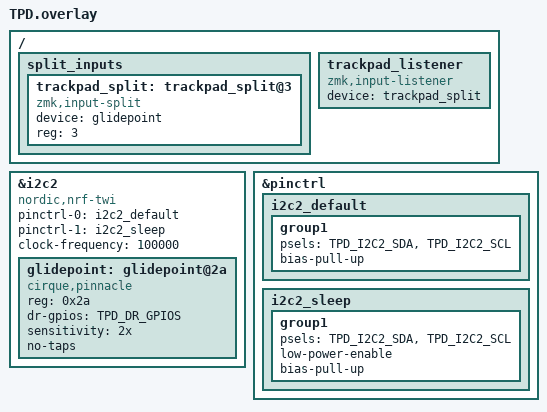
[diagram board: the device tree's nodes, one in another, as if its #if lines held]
&i2c2 {
    status = "okay";
    compatible = "nordic,nrf-twi";
    pinctrl-0 = <&i2c2_default>;
    pinctrl-1 = <&i2c2_sleep>;
    pinctrl-names = "default", "sleep";
    clock-frequency = <100000>;

    glidepoint: glidepoint@2a {
        compatible = "cirque,pinnacle";
        reg = <0x2a>;
        status = "okay";
        dr-gpios = TPD_DR_GPIOS;
        sensitivity = "2x";
        no-taps;
    };
};

&pinctrl {
    i2c2_default: i2c2_default {
        group1 {
            psels = <TPD_I2C2_SDA>,
                    <TPD_I2C2_SCL>;
            bias-pull-up;
        };
    };

    i2c2_sleep: i2c2_sleep {
        group1 {
            psels = <TPD_I2C2_SDA>,
                    <TPD_I2C2_SCL>;
            low-power-enable;
            bias-pull-up;
        };
    };
};

#if defined(CONFIG_SHIELD_SAA_L_Base)
&trackpad_split {
    status = "okay";
    device = <&glidepoint>;
};
#endif

#if defined(CONFIG_SHIELD_SAA_R_Base)
/ {
    split_inputs {
        #address-cells = <1>;
        #size-cells = <0>;

        trackpad_split: trackpad_split@3 {
            compatible = "zmk,input-split";
            status = "okay";
            device = <&glidepoint>;
            reg = <3>;
        };
    };

    trackpad_listener: trackpad_listener {
        compatible = "zmk,input-listener";
        status = "okay";
        device = <&trackpad_split>;
    };
};
#endif
